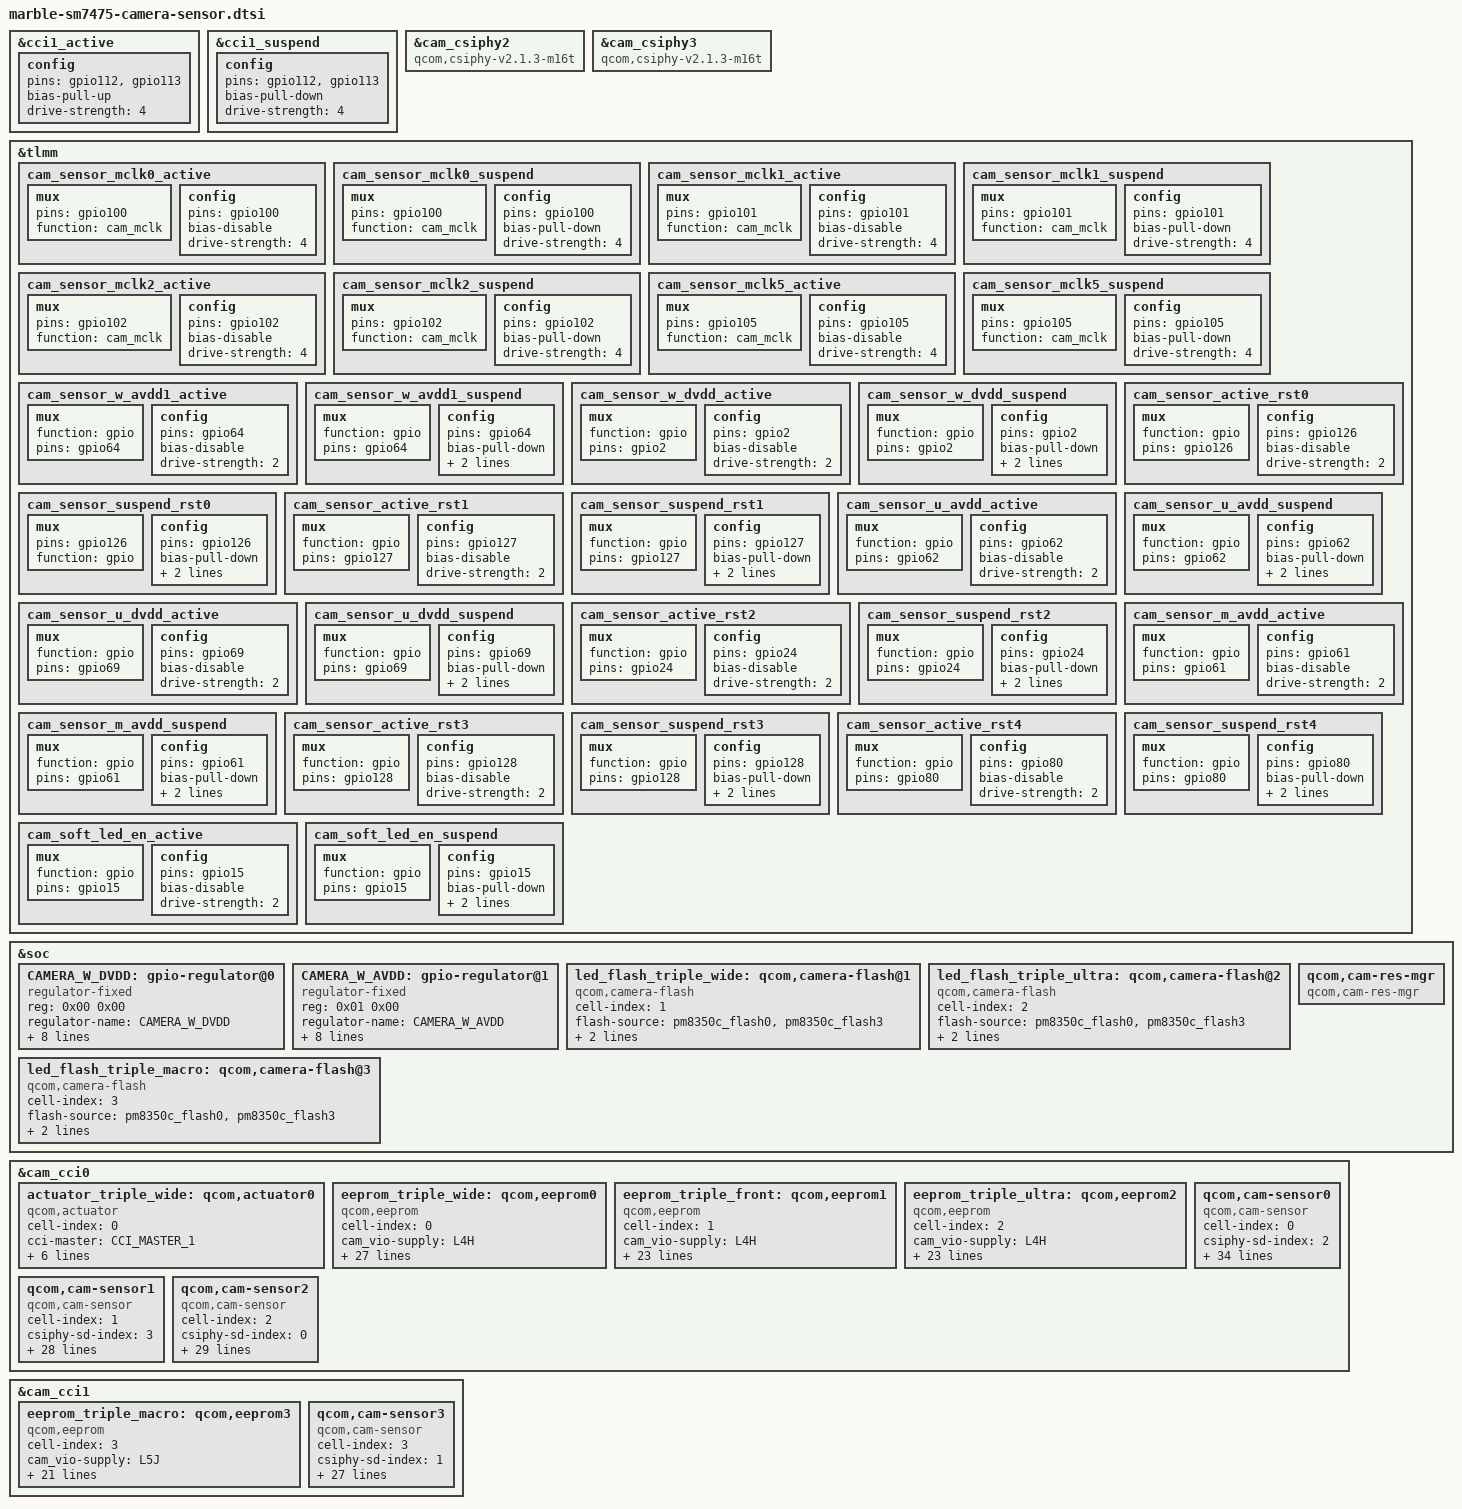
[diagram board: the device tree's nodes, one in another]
#include <dt-bindings/clock/qcom,camcc-waipio.h>
#include <dt-bindings/gpio/gpio.h>
#include <dt-bindings/msm-camera.h>

&cci1_active {
	config {
		pins = "gpio112", "gpio113";
		bias-pull-up; /* PULL UP */
		drive-strength = <4>; /* 4 MA */
	};
};

&cci1_suspend {
	config {
		pins = "gpio112", "gpio113";
		bias-pull-down; /* PULL DOWN */
		drive-strength = <4>; /* 4 MA */
	};
};

&cam_csiphy2 {
	compatible = "qcom,csiphy-v2.1.3-m16t", "qcom,csiphy";
};

&cam_csiphy3 {
	compatible = "qcom,csiphy-v2.1.3-m16t", "qcom,csiphy";
};

&tlmm {
	cam_sensor_mclk0_active: cam_sensor_mclk0_active {
		/* MCLK0 */
		mux {
			pins = "gpio100";
			function = "cam_mclk";
		};

		config {
			pins = "gpio100";
			bias-disable; /* No PULL */
			drive-strength = <4>; /* 4 MA */
		};
	};

	cam_sensor_mclk0_suspend: cam_sensor_mclk0_suspend {
		/* MCLK0 */
		mux {
			pins = "gpio100";
			function = "cam_mclk";
		};

		config {
			pins = "gpio100";
			bias-pull-down; /* PULL DOWN */
			drive-strength = <4>; /* 4 MA */
		};
	};

	cam_sensor_mclk1_active: cam_sensor_mclk1_active {
		/* MCLK1 */
		mux {
			pins = "gpio101";
			function = "cam_mclk";
		};

		config {
			pins = "gpio101";
			bias-disable; /* No PULL */
			drive-strength = <4>; /* 4 MA */
		};
	};

	cam_sensor_mclk1_suspend: cam_sensor_mclk1_suspend {
		/* MCLK1 */
		mux {
			pins = "gpio101";
			function = "cam_mclk";
		};

		config {
			pins = "gpio101";
			bias-pull-down; /* PULL DOWN */
			drive-strength = <4>; /* 4 MA */
		};
	};

	cam_sensor_mclk2_active: cam_sensor_mclk2_active {
		/* MCLK2 */
		mux {
			pins = "gpio102";
			function = "cam_mclk";
		};

		config {
			pins = "gpio102";
			bias-disable; /* No PULL */
			drive-strength = <4>; /* 4 MA */
		};
	};

	cam_sensor_mclk2_suspend: cam_sensor_mclk2_suspend {
		/* MCLK2 */
		mux {
			pins = "gpio102";
			function = "cam_mclk";
		};

		config {
			pins = "gpio102";
			bias-pull-down; /* PULL DOWN */
			drive-strength = <4>; /* 4 MA */
		};
	};

	cam_sensor_mclk5_active: cam_sensor_mclk5_active {
		/* MCLK5 */
		mux {
			pins = "gpio105";
			function = "cam_mclk";
		};

		config {
			pins = "gpio105";
			bias-disable; /* No PULL */
			drive-strength = <4>; /* 4 MA */
		};
	};

	cam_sensor_mclk5_suspend: cam_sensor_mclk5_suspend {
		/* MCLK5 */
		mux {
			pins = "gpio105";
			function = "cam_mclk";
		};

		config {
			pins = "gpio105";
			bias-pull-down; /* PULL DOWN */
			drive-strength = <4>; /* 4 MA */
		};
	};

	cam_sensor_w_avdd1_active: cam_sensor_w_avdd1_active {
		/* SENSOR WIDE AVDD ENABLE */
		mux {
			function = "gpio";
			pins = "gpio64";
		};

		config {
			pins = "gpio64";
			bias-disable; /* No PULL */
			drive-strength = <2>; /* 2 MA */
		};
	};

	cam_sensor_w_avdd1_suspend: cam_sensor_w_avdd1_suspend {
		/* SENSOR WIDE AVDD DISABLE */
		mux {
			function = "gpio";
			pins = "gpio64";
		};

		config {
			pins = "gpio64";
			bias-pull-down; /* PULL DOWN */
			drive-strength = <2>; /* 2 MA */
			output-low;
		};
	};

	cam_sensor_w_dvdd_active: cam_sensor_w_dvdd_active {
		/* SENSOR WIDE DVDD ENABLE */
		mux {
			function = "gpio";
			pins = "gpio2";
		};

		config {
			pins = "gpio2";
			bias-disable; /* No PULL */
			drive-strength = <2>; /* 2 MA */
		};
	};

	cam_sensor_w_dvdd_suspend: cam_sensor_w_dvdd_suspend {
		/* SENSOR WIDE DVDD DISABLE */
		mux {
			function = "gpio";
			pins = "gpio2";
		};

		config {
			pins = "gpio2";
			bias-pull-down; /* PULL DOWN */
			drive-strength = <2>; /* 2 MA */
			output-low;
		};
	};

	cam_sensor_active_rst0: cam_sensor_active_rst0 {
		/* RESET REAR */
		mux {
			function = "gpio";
			pins = "gpio126";
		};

		config {
			pins = "gpio126";
			bias-disable; /* No PULL */
			drive-strength = <2>; /* 2 MA */
		};
	};

	cam_sensor_suspend_rst0: cam_sensor_suspend_rst0 {
		/* RESET REAR */
		mux {
			pins = "gpio126";
			function = "gpio";
		};

		config {
			pins = "gpio126";
			bias-pull-down; /* PULL DOWN */
			drive-strength = <2>; /* 2 MA */
			output-low;
		};
	};

	cam_sensor_active_rst1: cam_sensor_active_rst1 {
		/* RESET REARAUX */
		mux {
			function = "gpio";
			pins = "gpio127";
		};

		config {
			pins = "gpio127";
			bias-disable; /* No PULL */
			drive-strength = <2>; /* 2 MA */
		};
	};

	cam_sensor_suspend_rst1: cam_sensor_suspend_rst1 {
		/* RESET REARAUX */
		mux {
			function = "gpio";
			pins = "gpio127";
		};

		config {
			pins = "gpio127";
			bias-pull-down; /* PULL DOWN */
			drive-strength = <2>; /* 2 MA */
			output-low;
		};
	};

	cam_sensor_u_avdd_active: cam_sensor_u_avdd_active {
		/* SENSOR ULTRA AVDD ENABLE */
		mux {
			function = "gpio";
			pins = "gpio62";
		};

		config {
			pins = "gpio62";
			bias-disable; /* No PULL */
			drive-strength = <2>; /* 2 MA */
		};
	};

	cam_sensor_u_avdd_suspend: cam_sensor_u_avdd_suspend {
		/* SENSOR ULTRA AVDD DISABLE */
		mux {
			function = "gpio";
			pins = "gpio62";
		};

		config {
			pins = "gpio62";
			bias-pull-down; /* PULL DOWN */
			drive-strength = <2>; /* 2 MA */
			output-low;
		};
	};

	cam_sensor_u_dvdd_active: cam_sensor_u_dvdd_active {
		/* SENSOR ULTRA DVDD DISABLE */
		mux {
			function = "gpio";
			pins = "gpio69";
		};

		config {
			pins = "gpio69";
			bias-disable; /* No PULL */
			drive-strength = <2>; /* 2 MA */
		};
	};

	cam_sensor_u_dvdd_suspend: cam_sensor_u_dvdd_suspend {
		/* SENSOR ULTRA DVDD DISABLE */
		mux {
			function = "gpio";
			pins = "gpio69";
		};

		config {
			pins = "gpio69";
			bias-pull-down; /* PULL DOWN */
			drive-strength = <2>; /* 2 MA */
			output-low;
		};
	};

	cam_sensor_active_rst2: cam_sensor_active_rst2 {
		/* RESET 2 */
		mux {
			function = "gpio";
			pins = "gpio24";
		};

		config {
			pins = "gpio24";
			bias-disable; /* No PULL */
			drive-strength = <2>; /* 2 MA */
		};
	};

	cam_sensor_suspend_rst2: cam_sensor_suspend_rst2 {
		/* RESET 2 */
		mux {
			function = "gpio";
			pins = "gpio24";
		};

		config {
			pins = "gpio24";
			bias-pull-down; /* PULL DOWN */
			drive-strength = <2>; /* 2 MA */
			output-low;
		};
	};

	cam_sensor_m_avdd_active: cam_sensor_m_avdd_active {
		/* SENSOR MACRO AVDD ENABLE */
		mux {
			function = "gpio";
			pins = "gpio61";
		};

		config {
			pins = "gpio61";
			bias-disable; /* No PULL */
			drive-strength = <2>; /* 2 MA */
		};
	};

	cam_sensor_m_avdd_suspend: cam_sensor_m_avdd_suspend {
		/* SENSOR MACRO AVDD DISABLE */
		mux {
			function = "gpio";
			pins = "gpio61";
		};

		config {
			pins = "gpio61";
			bias-pull-down; /* PULL DOWN */
			drive-strength = <2>; /* 2 MA */
			output-low;
		};
	};

	cam_sensor_active_rst3: cam_sensor_active_rst3 {
		/* RESET 3 */
		mux {
			function = "gpio";
			pins = "gpio128";
		};

		config {
			pins = "gpio128";
			bias-disable; /* No PULL */
			drive-strength = <2>; /* 2 MA */
		};
	};

	cam_sensor_suspend_rst3: cam_sensor_suspend_rst3 {
		/* RESET 3 */
		mux {
			function = "gpio";
			pins = "gpio128";
		};

		config {
			pins = "gpio128";
			bias-pull-down; /* PULL DOWN */
			drive-strength = <2>; /* 2 MA */
			output-low;
		};
	};

	cam_sensor_active_rst4: cam_sensor_active_rst4 {
		/* RESET 4 */
		mux {
			function = "gpio";
			pins = "gpio80";
		};

		config {
			pins = "gpio80";
			bias-disable; /* No PULL */
			drive-strength = <2>; /* 2 MA */
		};
	};

	cam_sensor_suspend_rst4: cam_sensor_suspend_rst4 {
		/* RESET 4 */
		mux {
			function = "gpio";
			pins = "gpio80";
		};

		config {
			pins = "gpio80";
			bias-pull-down; /* PULL DOWN */
			drive-strength = <2>; /* 2 MA */
			output-low;
		};
	};

	cam_soft_led_en_active: cam_soft_led_en_active {
		/* LED ENABLE */
		mux {
			function = "gpio";
			pins = "gpio15";
		};

		config {
			pins = "gpio15";
			bias-disable; /* No PULL */
			drive-strength = <2>; /* 2 MA */
		};
	};

	cam_soft_led_en_suspend: cam_soft_led_en_suspend {
		/* LED DISABLE */
		mux {
			function = "gpio";
			pins = "gpio15";
		};

		config {
			pins = "gpio15";
			bias-pull-down; /* PULL DOWN */
			drive-strength = <2>; /* 2 MA */
			output-low;
		};
	};
};

&soc {
	CAMERA_W_DVDD: gpio-regulator@0 {
		compatible = "regulator-fixed";
		reg = <0x00 0x00>;
		regulator-name = "CAMERA_W_DVDD";
		regulator-min-microvolt = <1100000>;
		regulator-max-microvolt = <1100000>;
		regulator-enable-ramp-delay = <100>;
		enable-active-high;
		gpio = <&tlmm 2 GPIO_ACTIVE_HIGH>;
		pinctrl-names = "default", "sleep";
		pinctrl-0 = <&cam_sensor_w_dvdd_active
					&cam_sensor_w_dvdd_suspend>;
		vin-supply = <&S12B>;
	};

	CAMERA_W_AVDD: gpio-regulator@1 {
		compatible = "regulator-fixed";
		reg = <0x01 0x00>;
		regulator-name = "CAMERA_W_AVDD";
		regulator-min-microvolt = <2800000>;
		regulator-max-microvolt = <2800000>;
		regulator-enable-ramp-delay = <100>;
		enable-active-high;
		gpio = <&tlmm 64 GPIO_ACTIVE_HIGH>;
		pinctrl-names = "default", "sleep";
		pinctrl-0 = <&cam_sensor_w_avdd1_active
					&cam_sensor_w_avdd1_suspend>;
		vin-supply = <&BOB>;
	};

	led_flash_triple_wide: qcom,camera-flash@1 {
		cell-index = <1>;
		compatible = "qcom,camera-flash";
		flash-source = <&pm8350c_flash0 &pm8350c_flash3>;
		switch-source = <&pm8350c_switch0>;
		torch-source = <&pm8350c_torch0 &pm8350c_torch3>;
		status = "ok";
	};

	led_flash_triple_ultra: qcom,camera-flash@2 {
		cell-index = <2>;
		compatible = "qcom,camera-flash";
		flash-source = <&pm8350c_flash0 &pm8350c_flash3>;
		switch-source = <&pm8350c_switch0>;
		torch-source = <&pm8350c_torch0 &pm8350c_torch3>;
		status = "ok";
	};

	led_flash_triple_macro: qcom,camera-flash@3 {
		cell-index = <3>;
		compatible = "qcom,camera-flash";
		flash-source = <&pm8350c_flash0 &pm8350c_flash3>;
		switch-source = <&pm8350c_switch0>;
		torch-source = <&pm8350c_torch0 &pm8350c_torch3>;
		status = "ok";
	};

	qcom,cam-res-mgr {
		status = "ok";
		compatible = "qcom,cam-res-mgr";
	};
};

&cam_cci0 {
	actuator_triple_wide: qcom,actuator0 {
		cell-index = <0>;
		compatible = "qcom,actuator";
		cci-master = <CCI_MASTER_1>;
		cam_vaf-supply = <&L6J>;
		regulator-names = "cam_vaf";
		rgltr-cntrl-support;
		rgltr-min-voltage = <2800000>;
		rgltr-max-voltage = <2800000>;
		rgltr-load-current = <300000>;
		status = "ok";
	};

	eeprom_triple_wide: qcom,eeprom0 {
		cell-index = <0>;
		compatible = "qcom,eeprom";
		cam_vio-supply = <&L4H>;
		cam_vdig-supply = <&CAMERA_W_DVDD>;
		cam_clk-supply = <&cam_cc_titan_top_gdsc>;
		cam_vana-supply = <&CAMERA_W_AVDD>;
		cam_vaf-supply = <&L6J>;
		regulator-names = "cam_vio", "cam_vana",
			"cam_vdig", "cam_vaf", "cam_clk";
		rgltr-cntrl-support;
		rgltr-min-voltage = <1800000 2800000 1100000 2800000 0>;
		rgltr-max-voltage = <1800000 2800000 1100000 2800000 0>;
		rgltr-load-current = <3500 164100 1251000 300000 0>;
		gpio-no-mux = <0>;
		pinctrl-names = "cam_default", "cam_suspend";
		pinctrl-0 = <&cam_sensor_mclk2_active
					&cam_sensor_active_rst0>;
		pinctrl-1 = <&cam_sensor_mclk2_suspend
					&cam_sensor_suspend_rst0>;
		gpios = <&tlmm 102 GPIO_ACTIVE_HIGH>,
			<&tlmm 126 GPIO_ACTIVE_HIGH>;
		gpio-reset = <1>;
		gpio-req-tbl-num = <0 1>;
		gpio-req-tbl-flags = <1 0>;
		gpio-req-tbl-label = "CAMIF_MCLK2",
					"CAM_RESET0";
		cci-master = <CCI_MASTER_1>;
		clocks = <&clock_camcc CAM_CC_MCLK2_CLK>;
		clock-names = "cam_clk";
		clock-cntl-level = "nominal";
		clock-rates = <19200000>;
		status = "ok";
	};

	eeprom_triple_front: qcom,eeprom1 {
		cell-index = <1>;
		compatible = "qcom,eeprom";
		cam_vio-supply = <&L4H>;
		cam_vdig-supply = <&L1J>;
		cam_clk-supply = <&cam_cc_titan_top_gdsc>;
		cam_vana-supply = <&L7J>;
		regulator-names = "cam_vio", "cam_vana",
			"cam_vdig", "cam_clk";
		rgltr-cntrl-support;
		rgltr-min-voltage = <1800000 2800000 1000000 0>;
		rgltr-max-voltage = <1800000 2800000 1000000 0>;
		rgltr-load-current = <3500 164100 5000 0>;
		gpio-no-mux = <0>;
		pinctrl-names = "cam_default", "cam_suspend";
		pinctrl-0 = <&cam_sensor_mclk5_active
					&cam_sensor_active_rst1>;
		pinctrl-1 = <&cam_sensor_mclk5_suspend
					&cam_sensor_suspend_rst1>;
		gpios = <&tlmm 105 GPIO_ACTIVE_HIGH>,
			<&tlmm 127 GPIO_ACTIVE_HIGH>;
		gpio-reset = <1>;
		gpio-req-tbl-num = <0 1>;
		gpio-req-tbl-flags = <1 0>;
		gpio-req-tbl-label = "CAMIF_MCLK5",
					"CAM_RESET1";
		cci-master = <CCI_MASTER_0>;
		clocks = <&clock_camcc CAM_CC_MCLK5_CLK>;
		clock-names = "cam_clk";
		clock-cntl-level = "nominal";
		clock-rates = <19200000>;
		status = "ok";
	};

	eeprom_triple_ultra: qcom,eeprom2 {
		cell-index = <2>;
		compatible = "qcom,eeprom";
		cam_vio-supply = <&L4H>;
		cam_vdig-supply = <&L2J>;
		cam_clk-supply = <&cam_cc_titan_top_gdsc>;
		cam_vana-supply = <&L3J>;
		regulator-names = "cam_vio", "cam_vana",
			"cam_vdig", "cam_clk";
		rgltr-cntrl-support;
		rgltr-min-voltage = <1800000 2800000 1200000 0>;
		rgltr-max-voltage = <1800000 2800000 1200000 0>;
		rgltr-load-current = <3500 164100 1251000 0>;
		gpio-no-mux = <0>;
		pinctrl-names = "cam_default", "cam_suspend";
		pinctrl-0 = <&cam_sensor_mclk1_active
					&cam_sensor_active_rst2>;
		pinctrl-1 = <&cam_sensor_mclk1_suspend
					&cam_sensor_suspend_rst2>;
		gpios = <&tlmm 101 GPIO_ACTIVE_HIGH>,
			<&tlmm 24 GPIO_ACTIVE_HIGH>;
		gpio-reset = <1>;
		gpio-req-tbl-num = <0 1>;
		gpio-req-tbl-flags = <1 0>;
		gpio-req-tbl-label = "CAMIF_MCLK1",
					"CAM_RESET2";
		cci-master = <CCI_MASTER_0>;
		clocks = <&clock_camcc CAM_CC_MCLK1_CLK>;
		clock-names = "cam_clk";
		clock-cntl-level = "nominal";
		clock-rates = <19200000>;
		status = "ok";
	};

	qcom,cam-sensor0 {
		cell-index = <0>;
		compatible = "qcom,cam-sensor";
		csiphy-sd-index = <2>;
		sensor-position-roll = <90>;
		sensor-position-pitch = <0>;
		sensor-position-yaw = <180>;
		eeprom-src = <&eeprom_triple_wide>;
		actuator-src = <&actuator_triple_wide>;
		led-flash-src = <&led_flash_triple_wide>;
		cam_vaf-supply = <&L6J>;
		cam_vana-supply = <&CAMERA_W_AVDD>;
		cam_clk-supply = <&cam_cc_titan_top_gdsc>;
		cam_vdig-supply = <&CAMERA_W_DVDD>;
		cam_vio-supply = <&L4H>;
		regulator-names = "cam_vio", "cam_vana",
			"cam_vdig", "cam_vaf", "cam_clk";
		rgltr-cntrl-support;
		rgltr-min-voltage = <1800000 2800000 1100000 2800000 0>;
		rgltr-max-voltage = <1800000 2800000 1100000 2800000 0>;
		rgltr-load-current = <3500 0x28104 164100 300000 0>;
		gpio-no-mux = <0>;
		pinctrl-names = "cam_default", "cam_suspend";
		pinctrl-0 = <&cam_sensor_mclk2_active
					&cam_sensor_active_rst0>;
		pinctrl-1 = <&cam_sensor_mclk2_suspend
					&cam_sensor_suspend_rst0>;
		gpios = <&tlmm 102 GPIO_ACTIVE_HIGH>,
			<&tlmm 126 GPIO_ACTIVE_HIGH>;
		gpio-reset = <1>;
		gpio-req-tbl-num = <0 1>;
		gpio-req-tbl-flags = <1 0>;
		gpio-req-tbl-label = "CAMIF_MCLK2",
					"CAM_RESET0";
		cci-master = <CCI_MASTER_1>;
		clocks = <&clock_camcc CAM_CC_MCLK2_CLK>;
		clock-names = "cam_clk";
		clock-cntl-level = "nominal";
		clock-rates = <19200000>;
		status = "ok";
	};

	qcom,cam-sensor1 {
		cell-index = <1>;
		compatible = "qcom,cam-sensor";
		csiphy-sd-index = <3>;
		sensor-position-roll = <270>;
		sensor-position-pitch = <0>;
		sensor-position-yaw = <0>;
		eeprom-src = <&eeprom_triple_front>;
		cam_vio-supply = <&L4H>;
		cam_vdig-supply = <&L1J>;
		cam_clk-supply = <&cam_cc_titan_top_gdsc>;
		cam_vana-supply = <&L7J>;
		regulator-names = "cam_vio", "cam_vana",
			"cam_vdig", "cam_clk";
		rgltr-cntrl-support;
		rgltr-min-voltage = <1800000 2800000 1000000 0>;
		rgltr-max-voltage = <1800000 2800000 1000000 0>;
		rgltr-load-current = <3500 164100 5000 0>;
		gpio-no-mux = <0>;
		pinctrl-names = "cam_default", "cam_suspend";
		pinctrl-0 = <&cam_sensor_mclk5_active
					&cam_sensor_active_rst1>;
		pinctrl-1 = <&cam_sensor_mclk5_suspend
					&cam_sensor_suspend_rst1>;
		gpios = <&tlmm 105 GPIO_ACTIVE_HIGH>,
			<&tlmm 127 GPIO_ACTIVE_HIGH>;
		gpio-reset = <1>;
		gpio-req-tbl-num = <0 1>;
		gpio-req-tbl-flags = <1 0>;
		gpio-req-tbl-label = "CAMIF_MCLK5",
					"CAM_RESET1";
		cci-master = <CCI_MASTER_0>;
		clocks = <&clock_camcc CAM_CC_MCLK5_CLK>;
		clock-names = "cam_clk";
		clock-cntl-level = "nominal";
		clock-rates = <19200000>;
		status = "ok";
	};

	qcom,cam-sensor2 {
		cell-index = <2>;
		compatible = "qcom,cam-sensor";
		csiphy-sd-index = <0>;
		sensor-position-roll = <90>;
		sensor-position-pitch = <0>;
		sensor-position-yaw = <180>;
		eeprom-src = <&eeprom_triple_ultra>;
		led-flash-src = <&led_flash_triple_ultra>;
		cam_vio-supply = <&L4H>;
		cam_vdig-supply = <&L2J>;
		cam_clk-supply = <&cam_cc_titan_top_gdsc>;
		cam_vana-supply = <&L3J>;
		regulator-names = "cam_vio", "cam_vana",
			"cam_vdig", "cam_clk";
		rgltr-cntrl-support;
		rgltr-min-voltage = <1800000 2800000 1200000 0>;
		rgltr-max-voltage = <1800000 2800000 1200000 0>;
		rgltr-load-current = <3500 164100 1251000 0>;
		gpio-no-mux = <0>;
		pinctrl-names = "cam_default", "cam_suspend";
		pinctrl-0 = <&cam_sensor_mclk1_active
					&cam_sensor_active_rst2>;
		pinctrl-1 = <&cam_sensor_mclk1_suspend
					&cam_sensor_suspend_rst2>;
		gpios = <&tlmm 101 GPIO_ACTIVE_HIGH>,
			<&tlmm 24 GPIO_ACTIVE_HIGH>;
		gpio-reset = <1>;
		gpio-req-tbl-num = <0 1>;
		gpio-req-tbl-flags = <1 0>;
		gpio-req-tbl-label = "CAMIF_MCLK1",
					"CAM_RESET2";
		cci-master = <CCI_MASTER_0>;
		clocks = <&clock_camcc CAM_CC_MCLK1_CLK>;
		clock-names = "cam_clk";
		clock-cntl-level = "nominal";
		clock-rates = <19200000>;
		status = "ok";
	};
};

&cam_cci1 {
	eeprom_triple_macro: qcom,eeprom3 {
		cell-index = <3>;
		compatible = "qcom,eeprom";
		cam_vio-supply = <&L5J>;
		cam_vana-supply = <&L4J>;
		cam_clk-supply = <&cam_cc_titan_top_gdsc>;
		regulator-names = "cam_vio", "cam_vana",
			"cam_clk";
		rgltr-cntrl-support;
		rgltr-min-voltage = <1800000 2800000 0>;
		rgltr-max-voltage = <1800000 2800000 0>;
		rgltr-load-current = <3500 164100 0>;
		gpio-no-mux = <0>;
		pinctrl-names = "cam_default", "cam_suspend";
		pinctrl-0 = <&cam_sensor_mclk0_active
					&cam_sensor_active_rst3>;
		pinctrl-1 = <&cam_sensor_mclk0_suspend
					&cam_sensor_suspend_rst3>;
		gpios = <&tlmm 100 GPIO_ACTIVE_HIGH>,
			<&tlmm 128 GPIO_ACTIVE_HIGH>;
		gpio-reset = <1>;
		gpio-req-tbl-num = <0 1>;
		gpio-req-tbl-flags = <1 0>;
		gpio-req-tbl-label = "CAMIF_MCLK0",
					"CAM_RESET3";
		cci-master = <CCI_MASTER_0>;
		clocks = <&clock_camcc CAM_CC_MCLK0_CLK>;
		clock-names = "cam_clk";
		clock-cntl-level = "nominal";
		clock-rates = <19200000>;
		status = "ok";
	};

	qcom,cam-sensor3 {
		cell-index = <3>;
		compatible = "qcom,cam-sensor";
		csiphy-sd-index = <1>;
		sensor-position-roll = <90>;
		sensor-position-pitch = <0>;
		sensor-position-yaw = <180>;
		eeprom-src = <&eeprom_triple_macro>;
		led-flash-src = <&led_flash_triple_macro>;
		cam_vio-supply = <&L5J>;
		cam_vana-supply = <&L4J>;
		cam_clk-supply = <&cam_cc_titan_top_gdsc>;
		regulator-names = "cam_vio", "cam_vana",
			"cam_clk";
		rgltr-cntrl-support;
		rgltr-min-voltage = <1800000 2800000 0>;
		rgltr-max-voltage = <1800000 2800000 0>;
		rgltr-load-current = <3500 164100 0>;
		gpio-no-mux = <0>;
		pinctrl-names = "cam_default", "cam_suspend";
		pinctrl-0 = <&cam_sensor_mclk0_active
					&cam_sensor_active_rst3>;
		pinctrl-1 = <&cam_sensor_mclk0_suspend
					&cam_sensor_suspend_rst3>;
		gpios = <&tlmm 100 GPIO_ACTIVE_HIGH>,
			<&tlmm 128 GPIO_ACTIVE_HIGH>;
		gpio-reset = <1>;
		gpio-req-tbl-num = <0 1>;
		gpio-req-tbl-flags = <1 0>;
		gpio-req-tbl-label = "CAMIF_MCLK0",
					"CAM_RESET3";
		cci-master = <CCI_MASTER_0>;
		clocks = <&clock_camcc CAM_CC_MCLK0_CLK>;
		clock-names = "cam_clk";
		clock-cntl-level = "nominal";
		clock-rates = <19200000>;
		status = "ok";
	};
};
